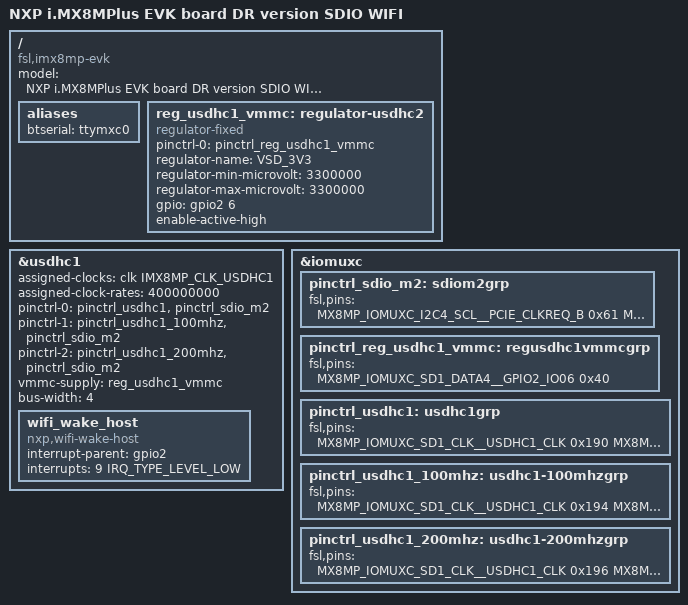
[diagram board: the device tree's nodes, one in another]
// SPDX-License-Identifier: (GPL-2.0+ OR MIT)
/*
 * Copyright 2019 NXP
 */

/dts-v1/;

#include "dr-imx8mp-evk.dtsi"

/ {
	model = "NXP i.MX8MPlus EVK board DR version SDIO WIFI";
	compatible = "fsl,imx8mp-evk", "fsl,imx8mp";

	aliases {
		btserial = "ttymxc0";
	};

	reg_usdhc1_vmmc: regulator-usdhc2 {
		compatible = "regulator-fixed";
		pinctrl-names = "default";
		pinctrl-0 = <&pinctrl_reg_usdhc1_vmmc>;
		regulator-name = "VSD_3V3";
		regulator-min-microvolt = <3300000>;
		regulator-max-microvolt = <3300000>;
		gpio = <&gpio2 6 GPIO_ACTIVE_HIGH>;
		enable-active-high;
	};
};

&usdhc1 {
	assigned-clocks = <&clk IMX8MP_CLK_USDHC1>;
	assigned-clock-rates = <400000000>;
	pinctrl-names = "default", "state_100mhz", "state_200mhz";
	pinctrl-0 = <&pinctrl_usdhc1>, <&pinctrl_sdio_m2>;
	pinctrl-1 = <&pinctrl_usdhc1_100mhz>, <&pinctrl_sdio_m2>;
	pinctrl-2 = <&pinctrl_usdhc1_200mhz>, <&pinctrl_sdio_m2> ;
	vmmc-supply = <&reg_usdhc1_vmmc>;
	bus-width = <4>;
	status = "okay";

	wifi_wake_host {
		compatible = "nxp,wifi-wake-host";
		interrupt-parent = <&gpio2>;
		interrupts = <9 IRQ_TYPE_LEVEL_LOW>;
		interrupt-names = "host-wake";
	};
};

&iomuxc {
	pinctrl_sdio_m2: sdiom2grp {
		fsl,pins = <
			MX8MP_IOMUXC_I2C4_SCL__PCIE_CLKREQ_B	0x61 /* open drain, pull up */
			MX8MP_IOMUXC_SD1_DATA6__GPIO2_IO08		0x40	/* BT wake */
			MX8MP_IOMUXC_SD1_DATA7__GPIO2_IO09		0x1c4	/* SD wake */
		>;
	};

	pinctrl_reg_usdhc1_vmmc: regusdhc1vmmcgrp {
		fsl,pins = <
			MX8MP_IOMUXC_SD1_DATA4__GPIO2_IO06		0x40
		>;
	};

	pinctrl_usdhc1: usdhc1grp {
		fsl,pins = <
			MX8MP_IOMUXC_SD1_CLK__USDHC1_CLK	0x190
			MX8MP_IOMUXC_SD1_CMD__USDHC1_CMD	0x1d0
			MX8MP_IOMUXC_SD1_DATA0__USDHC1_DATA0	0x1d0
			MX8MP_IOMUXC_SD1_DATA1__USDHC1_DATA1	0x1d0
			MX8MP_IOMUXC_SD1_DATA2__USDHC1_DATA2	0x1d0
			MX8MP_IOMUXC_SD1_DATA3__USDHC1_DATA3	0x1d0
		>;
	};

	pinctrl_usdhc1_100mhz: usdhc1-100mhzgrp {
		fsl,pins = <
			MX8MP_IOMUXC_SD1_CLK__USDHC1_CLK	0x194
			MX8MP_IOMUXC_SD1_CMD__USDHC1_CMD	0x1d4
			MX8MP_IOMUXC_SD1_DATA0__USDHC1_DATA0	0x1d4
			MX8MP_IOMUXC_SD1_DATA1__USDHC1_DATA1	0x1d4
			MX8MP_IOMUXC_SD1_DATA2__USDHC1_DATA2	0x1d4
			MX8MP_IOMUXC_SD1_DATA3__USDHC1_DATA3	0x1d4
		>;
	};

	pinctrl_usdhc1_200mhz: usdhc1-200mhzgrp {
		fsl,pins = <
			MX8MP_IOMUXC_SD1_CLK__USDHC1_CLK	0x196
			MX8MP_IOMUXC_SD1_CMD__USDHC1_CMD	0x1d6
			MX8MP_IOMUXC_SD1_DATA0__USDHC1_DATA0	0x1d6
			MX8MP_IOMUXC_SD1_DATA1__USDHC1_DATA1	0x1d6
			MX8MP_IOMUXC_SD1_DATA2__USDHC1_DATA2	0x1d6
			MX8MP_IOMUXC_SD1_DATA3__USDHC1_DATA3	0x1d6
		>;
	};
};
